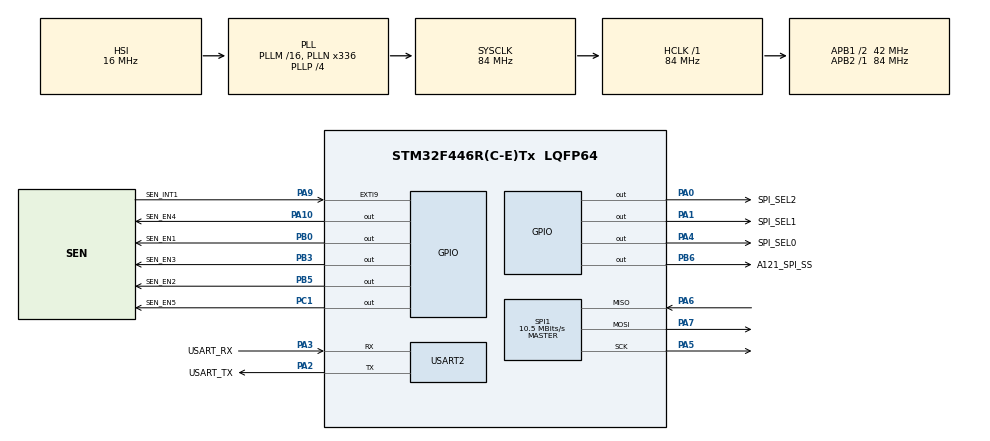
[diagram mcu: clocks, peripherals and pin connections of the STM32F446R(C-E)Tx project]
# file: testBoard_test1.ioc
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Mcu.Family=STM32F4
Mcu.Name=STM32F446R(C-E)Tx
Mcu.Package=LQFP64
NVIC.EXTI9_5_IRQn=true\:0\:0\:false\:false\:true\:true\:true\:true
NVIC.PriorityGroup=NVIC_PRIORITYGROUP_0
NVIC.USART2_IRQn=true\:0\:0\:false\:false\:true\:true\:true\:true
PA0-WKUP.GPIO_Label=SPI_SEL2
PA0-WKUP.GPIO_Speed=GPIO_SPEED_FREQ_VERY_HIGH
PA0-WKUP.Signal=GPIO_Output
PA1.GPIO_Label=SPI_SEL1 
PA1.GPIO_Speed=GPIO_SPEED_FREQ_VERY_HIGH
PA1.Signal=GPIO_Output
PA10.GPIO_Label=SEN_EN4
PA10.GPIO_Speed=GPIO_SPEED_FREQ_VERY_HIGH
PA10.Signal=GPIO_Output
PA13.GPIO_Label=TMS
PA13.Mode=Serial_Wire
PA13.Signal=SYS_JTMS-SWDIO
PA14.GPIO_Label=TCK
PA14.Mode=Serial_Wire
PA14.Signal=SYS_JTCK-SWCLK
PA2.GPIO_Label=USART_TX
PA2.Mode=Asynchronous
PA2.Signal=USART2_TX
PA3.GPIO_Label=USART_RX
PA3.Mode=Asynchronous
PA3.Signal=USART2_RX
PA4.GPIO_Label=SPI_SEL0
PA4.GPIO_Speed=GPIO_SPEED_FREQ_VERY_HIGH
PA4.Signal=GPIO_Output
PA5.Mode=Full_Duplex_Master
PA5.Signal=SPI1_SCK
PA6.Mode=Full_Duplex_Master
PA6.Signal=SPI1_MISO
PA7.Mode=Full_Duplex_Master
PA7.Signal=SPI1_MOSI
PA9.GPIO_Label=SEN_INT1
PA9.Signal=GPXTI9
PB0.GPIO_Label=SEN_EN1
PB0.GPIO_Speed=GPIO_SPEED_FREQ_VERY_HIGH
PB0.Signal=GPIO_Output
PB3.GPIO_Label=SEN_EN3
PB3.GPIO_Speed=GPIO_SPEED_FREQ_VERY_HIGH
PB3.Signal=GPIO_Output
PB5.GPIO_Label=SEN_EN2
PB5.GPIO_Speed=GPIO_SPEED_FREQ_VERY_HIGH
PB5.Signal=GPIO_Output
PB6.GPIO_Label=A121_SPI_SS
PB6.GPIO_Speed=GPIO_SPEED_FREQ_VERY_HIGH
PB6.PinState=GPIO_PIN_SET
PB6.Signal=GPIO_Output
PC1.GPIO_Label=SEN_EN5
PC1.GPIO_Speed=GPIO_SPEED_FREQ_VERY_HIGH
PC1.Signal=GPIO_Output
PC14-OSC32_IN.Mode=LSE-External-Oscillator
PC14-OSC32_IN.Signal=RCC_OSC32_IN
PC15-OSC32_OUT.Mode=LSE-External-Oscillator
PC15-OSC32_OUT.Signal=RCC_OSC32_OUT
PH0-OSC_IN.Mode=HSE-External-Oscillator
PH0-OSC_IN.Signal=RCC_OSC_IN
PH1-OSC_OUT.Mode=HSE-External-Oscillator
PH1-OSC_OUT.Signal=RCC_OSC_OUT
ProjectManager.HeapSize=0x200
ProjectManager.StackSize=0x400
ProjectManager.TargetToolchain=STM32CubeIDE
RCC.48MHZClocksFreq_Value=84000000
RCC.AHBFreq_Value=84000000
RCC.APB1CLKDivider=RCC_HCLK_DIV2
RCC.APB1Freq_Value=42000000
RCC.APB1TimFreq_Value=84000000
RCC.APB2Freq_Value=84000000
RCC.APB2TimFreq_Value=84000000
RCC.CortexFreq_Value=84000000
RCC.FLatency-AdvancedSettings=FLASH_LATENCY_2
RCC.HCLKFreq_Value=84000000
RCC.HSE_VALUE=8000000
RCC.HSI_VALUE=16000000
RCC.PLLN=336
RCC.PLLP=RCC_PLLP_DIV4
RCC.SYSCLKFreq_VALUE=84000000
RCC.SYSCLKSource=RCC_SYSCLKSOURCE_PLLCLK
RCC.USBFreq_Value=168000000
RCC.VCOOutputFreq_Value=336000000
SPI1.BaudRatePrescaler=SPI_BAUDRATEPRESCALER_8
SPI1.CalculateBaudRate=10.5 MBits/s
SPI1.Direction=SPI_DIRECTION_2LINES
SPI1.Mode=SPI_MODE_MASTER
SPI1.VirtualType=VM_MASTER
USART2.VirtualMode=VM_ASYNC
board=NUCLEO-F446RE

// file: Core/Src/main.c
/* USER CODE BEGIN Header */
/**
  ******************************************************************************
  * @file           : main.c
  * @brief          : Main program body
  ******************************************************************************
  * @attention
  *
  * Copyright (c) 2024 STMicroelectronics.
  * All rights reserved.
  *
  * This software is licensed under terms that can be found in the LICENSE file
  * in the root directory of this software component.
  * If no LICENSE file comes with this software, it is provided AS-IS.
  *
  ******************************************************************************
  */
/* USER CODE END Header */
#include "main.h"

SPI_HandleTypeDef hspi1;

UART_HandleTypeDef huart2;

/* USER CODE BEGIN PV */
uint8_t tx_buffer[27]="Welcome to Binary\n\r";
/* USER CODE END PV */

void SystemClock_Config(void);
static void MX_GPIO_Init(void);
static void MX_SPI1_Init(void);
static void MX_USART2_UART_Init(void);

/* USER CODE BEGIN 0 */
int _write(int file, char *ptr, int len)
{
    (void)file;
    HAL_UART_Transmit(&huart2, (uint8_t*)ptr, len, 0xFFFF);
    return len;
}

/* USER CODE END 0 */

int main(void)
{

  /* MCU Configuration--------------------------------------------------------*/

  /* Reset of all peripherals, Initializes the Flash interface and the Systick. */
  HAL_Init();

  /* Configure the system clock */
  SystemClock_Config();

  /* Initialize all configured peripherals */
  MX_GPIO_Init();
  MX_SPI1_Init();
  MX_USART2_UART_Init();
  /* USER CODE BEGIN 2 */
  acc_example_service(0,NULL);
  /* USER CODE END 2 */

  /* Infinite loop */
  /* USER CODE BEGIN WHILE */
  while (1)
  {
//	  HAL_GPIO_TogglePin(SEN_EN1_GPIO_Port,SEN_EN1_Pin);
//	  HAL_Delay(1000);
    /* USER CODE END WHILE */

    /* USER CODE BEGIN 3 */
//	  HAL_UART_Transmit(&huart2,tx_buffer,27,10);
//	  printf("Application finished OK\n");
//	  HAL_Delay(1000);
  }
  /* USER CODE END 3 */
}

void SystemClock_Config(void)
{
  RCC_OscInitTypeDef RCC_OscInitStruct = {0};
  RCC_ClkInitTypeDef RCC_ClkInitStruct = {0};

  /** Configure the main internal regulator output voltage
  */
  __HAL_RCC_PWR_CLK_ENABLE();
  __HAL_PWR_VOLTAGESCALING_CONFIG(PWR_REGULATOR_VOLTAGE_SCALE3);

  /** Initializes the RCC Oscillators according to the specified parameters
  * in the RCC_OscInitTypeDef structure.
  */
  RCC_OscInitStruct.OscillatorType = RCC_OSCILLATORTYPE_HSI;
  RCC_OscInitStruct.HSIState = RCC_HSI_ON;
  RCC_OscInitStruct.HSICalibrationValue = RCC_HSICALIBRATION_DEFAULT;
  RCC_OscInitStruct.PLL.PLLState = RCC_PLL_ON;
  RCC_OscInitStruct.PLL.PLLSource = RCC_PLLSOURCE_HSI;
  RCC_OscInitStruct.PLL.PLLM = 16;
  RCC_OscInitStruct.PLL.PLLN = 336;
  RCC_OscInitStruct.PLL.PLLP = RCC_PLLP_DIV4;
  RCC_OscInitStruct.PLL.PLLQ = 2;
  RCC_OscInitStruct.PLL.PLLR = 2;
  if (HAL_RCC_OscConfig(&RCC_OscInitStruct) != HAL_OK)
  {
    Error_Handler();
  }

  /** Initializes the CPU, AHB and APB buses clocks
  */
  RCC_ClkInitStruct.ClockType = RCC_CLOCKTYPE_HCLK|RCC_CLOCKTYPE_SYSCLK
                              |RCC_CLOCKTYPE_PCLK1|RCC_CLOCKTYPE_PCLK2;
  RCC_ClkInitStruct.SYSCLKSource = RCC_SYSCLKSOURCE_PLLCLK;
  RCC_ClkInitStruct.AHBCLKDivider = RCC_SYSCLK_DIV1;
  RCC_ClkInitStruct.APB1CLKDivider = RCC_HCLK_DIV2;
  RCC_ClkInitStruct.APB2CLKDivider = RCC_HCLK_DIV1;

  if (HAL_RCC_ClockConfig(&RCC_ClkInitStruct, FLASH_LATENCY_2) != HAL_OK)
  {
    Error_Handler();
  }
}

static void MX_SPI1_Init(void)
{

  /* SPI1 parameter configuration*/
  hspi1.Instance = SPI1;
  hspi1.Init.Mode = SPI_MODE_MASTER;
  hspi1.Init.Direction = SPI_DIRECTION_2LINES;
  hspi1.Init.DataSize = SPI_DATASIZE_8BIT;
  hspi1.Init.CLKPolarity = SPI_POLARITY_LOW;
  hspi1.Init.CLKPhase = SPI_PHASE_1EDGE;
  hspi1.Init.NSS = SPI_NSS_SOFT;
  hspi1.Init.BaudRatePrescaler = SPI_BAUDRATEPRESCALER_8;
  hspi1.Init.FirstBit = SPI_FIRSTBIT_MSB;
  hspi1.Init.TIMode = SPI_TIMODE_DISABLE;
  hspi1.Init.CRCCalculation = SPI_CRCCALCULATION_DISABLE;
  hspi1.Init.CRCPolynomial = 10;
  if (HAL_SPI_Init(&hspi1) != HAL_OK)
  {
    Error_Handler();
  }

}

static void MX_USART2_UART_Init(void)
{

  huart2.Instance = USART2;
  huart2.Init.BaudRate = 115200;
  huart2.Init.WordLength = UART_WORDLENGTH_8B;
  huart2.Init.StopBits = UART_STOPBITS_1;
  huart2.Init.Parity = UART_PARITY_NONE;
  huart2.Init.Mode = UART_MODE_TX_RX;
  huart2.Init.HwFlowCtl = UART_HWCONTROL_NONE;
  huart2.Init.OverSampling = UART_OVERSAMPLING_16;
  if (HAL_UART_Init(&huart2) != HAL_OK)
  {
    Error_Handler();
  }

}

static void MX_GPIO_Init(void)
{
  GPIO_InitTypeDef GPIO_InitStruct = {0};

  /* GPIO Ports Clock Enable */
  __HAL_RCC_GPIOC_CLK_ENABLE();
  __HAL_RCC_GPIOH_CLK_ENABLE();
  __HAL_RCC_GPIOA_CLK_ENABLE();
  __HAL_RCC_GPIOB_CLK_ENABLE();

  /*Configure GPIO pin Output Level */
  HAL_GPIO_WritePin(SEN_EN5_GPIO_Port, SEN_EN5_Pin, GPIO_PIN_RESET);

  /*Configure GPIO pin Output Level */
  HAL_GPIO_WritePin(GPIOA, SPI_SEL2_Pin|SPI_SEL1_Pin|SPI_SEL0_Pin|SEN_EN4_Pin, GPIO_PIN_RESET);

  /*Configure GPIO pin Output Level */
  HAL_GPIO_WritePin(GPIOB, SEN_EN1_Pin|SEN_EN3_Pin|SEN_EN2_Pin, GPIO_PIN_RESET);

  /*Configure GPIO pin Output Level */
  HAL_GPIO_WritePin(A121_SPI_SS_GPIO_Port, A121_SPI_SS_Pin, GPIO_PIN_SET);

  /*Configure GPIO pin : SEN_EN5_Pin */
  GPIO_InitStruct.Pin = SEN_EN5_Pin;
  GPIO_InitStruct.Mode = GPIO_MODE_OUTPUT_PP;
  GPIO_InitStruct.Pull = GPIO_NOPULL;
  GPIO_InitStruct.Speed = GPIO_SPEED_FREQ_VERY_HIGH;
  HAL_GPIO_Init(SEN_EN5_GPIO_Port, &GPIO_InitStruct);

  /*Configure GPIO pins : SPI_SEL2_Pin SPI_SEL1_Pin SPI_SEL0_Pin SEN_EN4_Pin */
  GPIO_InitStruct.Pin = SPI_SEL2_Pin|SPI_SEL1_Pin|SPI_SEL0_Pin|SEN_EN4_Pin;
  GPIO_InitStruct.Mode = GPIO_MODE_OUTPUT_PP;
  GPIO_InitStruct.Pull = GPIO_NOPULL;
  GPIO_InitStruct.Speed = GPIO_SPEED_FREQ_VERY_HIGH;
  HAL_GPIO_Init(GPIOA, &GPIO_InitStruct);

  /*Configure GPIO pins : SEN_EN1_Pin SEN_EN3_Pin SEN_EN2_Pin A121_SPI_SS_Pin */
  GPIO_InitStruct.Pin = SEN_EN1_Pin|SEN_EN3_Pin|SEN_EN2_Pin|A121_SPI_SS_Pin;
  GPIO_InitStruct.Mode = GPIO_MODE_OUTPUT_PP;
  GPIO_InitStruct.Pull = GPIO_NOPULL;
  GPIO_InitStruct.Speed = GPIO_SPEED_FREQ_VERY_HIGH;
  HAL_GPIO_Init(GPIOB, &GPIO_InitStruct);

  /*Configure GPIO pin : SEN_INT1_Pin */
  GPIO_InitStruct.Pin = SEN_INT1_Pin;
  GPIO_InitStruct.Mode = GPIO_MODE_IT_RISING;
  GPIO_InitStruct.Pull = GPIO_NOPULL;
  HAL_GPIO_Init(SEN_INT1_GPIO_Port, &GPIO_InitStruct);

  /* EXTI interrupt init*/
  HAL_NVIC_SetPriority(EXTI9_5_IRQn, 0, 0);
  HAL_NVIC_EnableIRQ(EXTI9_5_IRQn);

}

void Error_Handler(void)
{
  __disable_irq();
  while (1)
  {
  }
}
